# HT32F52342_52 register map
File version: 1.0
CPU: CM0+ r0p1, little endian, no MPU, no FPU, 4 interrupt priority bits
Registers are 32-bit, read-write, reset 0x0 unless marked. A register's access mark holds for its fields unless they carry their own. Offsets are from the block's base; [hi:lo] are bit positions; {n}, {i} and the like mark numbered series.

## USART0
Base 0x40000000
Same registers: USART1 0x40040000
0x00 USART_USRDR
  [8:0] DB
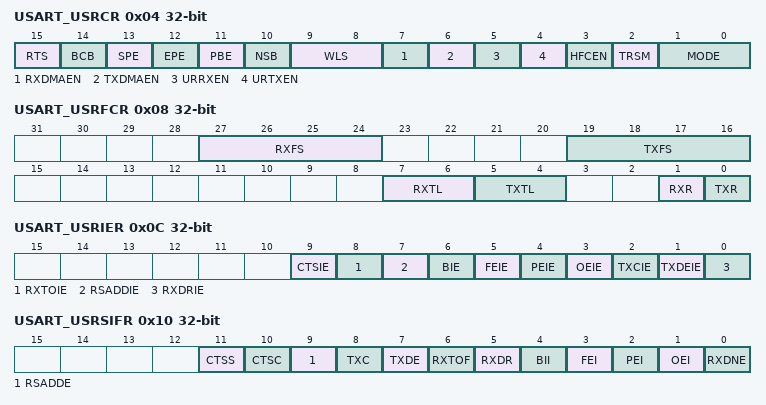
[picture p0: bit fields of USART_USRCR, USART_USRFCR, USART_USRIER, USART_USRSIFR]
0x04 USART_USRCR
  [15] RTS, [14] BCB, [13] SPE, [12] EPE, [11] PBE, [10] NSB, [9:8] WLS, [7] RXDMAEN, [6] TXDMAEN, [5] URRXEN, [4] URTXEN, [3] HFCEN, [2] TRSM, [1:0] MODE
0x08 USART_USRFCR
  [27:24] RXFS, [19:16] TXFS, [7:6] RXTL, [5:4] TXTL, [1] RXR, [0] TXR
0x0C USART_USRIER
  [9] CTSIE, [8] RXTOIE, [7] RSADDIE, [6] BIE, [5] FEIE, [4] PEIE, [3] OEIE, [2] TXCIE, [1] TXDEIE, [0] RXDRIE
0x10 USART_USRSIFR
  [11] CTSS, [10] CTSC, [9] RSADDE, [8] TXC, [7] TXDE, [6] RXTOF, [5] RXDR, [4] BII, [3] FEI, [2] PEI, [1] OEI, [0] RXDNE
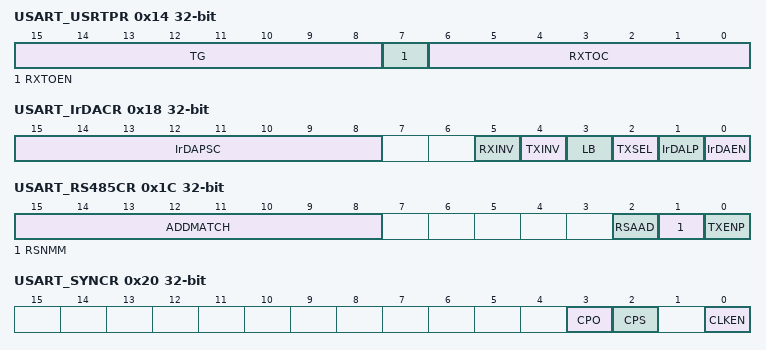
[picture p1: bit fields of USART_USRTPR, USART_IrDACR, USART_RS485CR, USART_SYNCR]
0x14 USART_USRTPR
  [15:8] TG, [7] RXTOEN, [6:0] RXTOC
0x18 USART_IrDACR
  [15:8] IrDAPSC, [5] RXINV, [4] TXINV, [3] LB, [2] TXSEL, [1] IrDALP, [0] IrDAEN
0x1C USART_RS485CR
  [15:8] ADDMATCH, [2] RSAAD, [1] RSNMM, [0] TXENP
0x20 USART_SYNCR
  [3] CPO, [2] CPS, [0] CLKEN
0x24 USART_USRDLR
  [15:0] BRD
0x28 USART_USRTSTR
  [1:0] LBM

## UART0
Base 0x40001000
Same registers: UART1 0x40041000
0x00 UART_URDR
  [8:0] DB
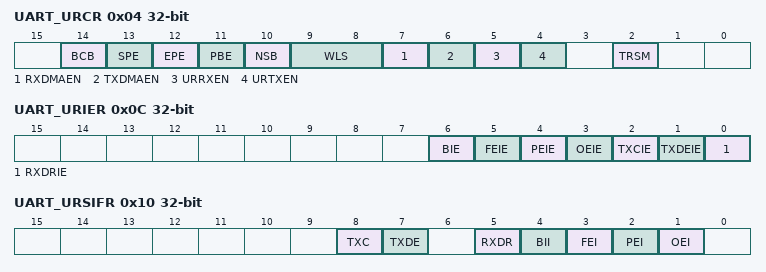
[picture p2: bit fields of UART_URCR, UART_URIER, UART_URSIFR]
0x04 UART_URCR
  [14] BCB, [13] SPE, [12] EPE, [11] PBE, [10] NSB, [9:8] WLS, [7] RXDMAEN, [6] TXDMAEN, [5] URRXEN, [4] URTXEN, [2] TRSM
0x0C UART_URIER
  [6] BIE, [5] FEIE, [4] PEIE, [3] OEIE, [2] TXCIE, [1] TXDEIE, [0] RXDRIE
0x10 UART_URSIFR
  [8] TXC, [7] TXDE, [5] RXDR, [4] BII, [3] FEI, [2] PEI, [1] OEI
0x24 UART_URDLR
  [15:0] BRD
0x28 UART_URTSTR
  [1:0] LBM

## SCI
Base 0x40043000
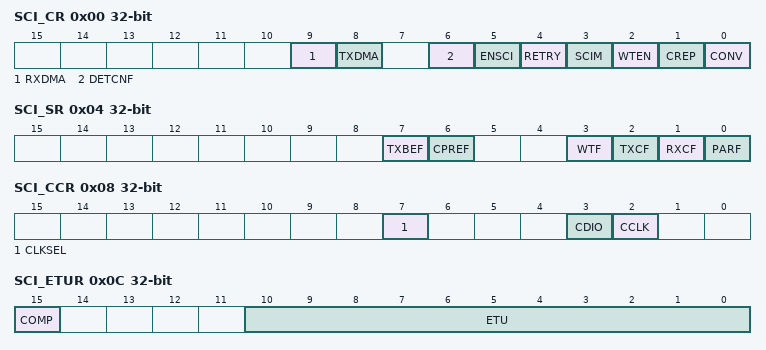
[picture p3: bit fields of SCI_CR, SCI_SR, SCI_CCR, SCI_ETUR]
0x00 SCI_CR
  [9] RXDMA, [8] TXDMA, [6] DETCNF, [5] ENSCI, [4] RETRY, [3] SCIM, [2] WTEN, [1] CREP, [0] CONV
0x04 SCI_SR
  [7] TXBEF, [6] CPREF, [3] WTF, [2] TXCF, [1] RXCF, [0] PARF
0x08 SCI_CCR
  [7] CLKSEL, [3] CDIO, [2] CCLK
0x0C SCI_ETUR
  [15] COMP, [10:0] ETU
0x10 SCI_GTR
  [8:0] GT
0x14 SCI_WTR
  [23:0] WT
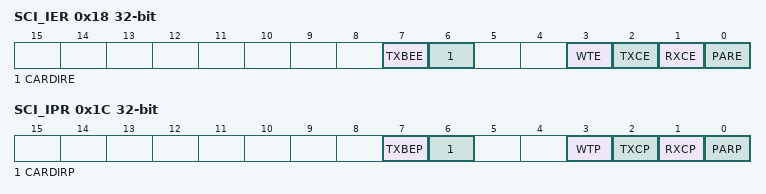
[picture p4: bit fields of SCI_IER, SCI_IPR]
0x18 SCI_IER
  [7] TXBEE, [6] CARDIRE, [3] WTE, [2] TXCE, [1] RXCE, [0] PARE
0x1C SCI_IPR
  [7] TXBEP, [6] CARDIRP, [3] WTP, [2] TXCP, [1] RXCP, [0] PARP
0x20 SCI_TXB
  [7:0] TB
0x24 SCI_RXB
  [7:0] RB
0x28 SCI_PSCR
  [5:0] PSC

## USB
Base 0x400A8000
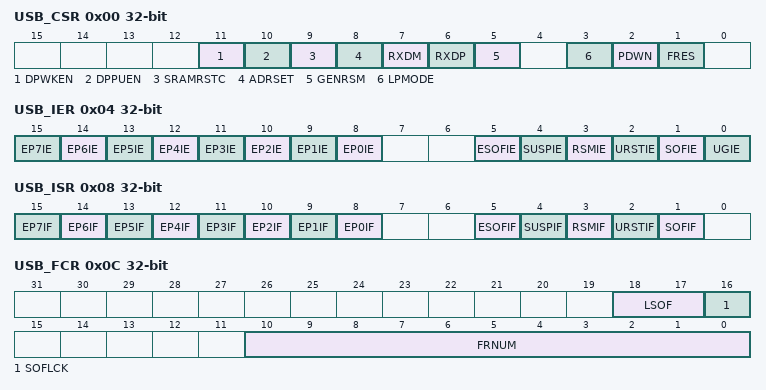
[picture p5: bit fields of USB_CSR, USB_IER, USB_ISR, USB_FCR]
0x00 USB_CSR
  [11] DPWKEN, [10] DPPUEN, [9] SRAMRSTC, [8] ADRSET, [7] RXDM, [6] RXDP, [5] GENRSM, [3] LPMODE, [2] PDWN, [1] FRES
0x04 USB_IER
  [n+8] EP{n}IE (n=0..7), [5] ESOFIE, [4] SUSPIE, [3] RSMIE, [2] URSTIE, [1] SOFIE, [0] UGIE
0x08 USB_ISR
  [n+8] EP{n}IF (n=0..7), [5] ESOFIF, [4] SUSPIF, [3] RSMIF, [2] URSTIF, [1] SOFIF
0x0C USB_FCR
  [18:17] LSOF, [16] SOFLCK, [10:0] FRNUM
0x10 USB_DEVAR
  [6:0] DEVA
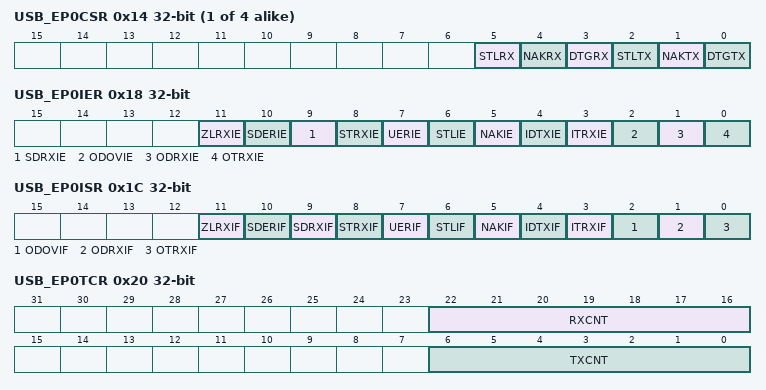
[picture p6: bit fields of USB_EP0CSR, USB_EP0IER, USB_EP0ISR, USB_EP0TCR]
{0x14+0x14*i} USB_EP{i}CSR (i=0..3)
  [5] STLRX, [4] NAKRX, [3] DTGRX, [2] STLTX, [1] NAKTX, [0] DTGTX
0x18 USB_EP0IER
  [11] ZLRXIE, [10] SDERIE, [9] SDRXIE, [8] STRXIE, [7] UERIE, [6] STLIE, [5] NAKIE, [4] IDTXIE, [3] ITRXIE, [2] ODOVIE, [1] ODRXIE, [0] OTRXIE
0x1C USB_EP0ISR
  [11] ZLRXIF, [10] SDERIF, [9] SDRXIF, [8] STRXIF, [7] UERIF, [6] STLIF, [5] NAKIF, [4] IDTXIF, [3] ITRXIF, [2] ODOVIF, [1] ODRXIF, [0] OTRXIF
0x20 USB_EP0TCR
  [22:16] RXCNT, [6:0] TXCNT
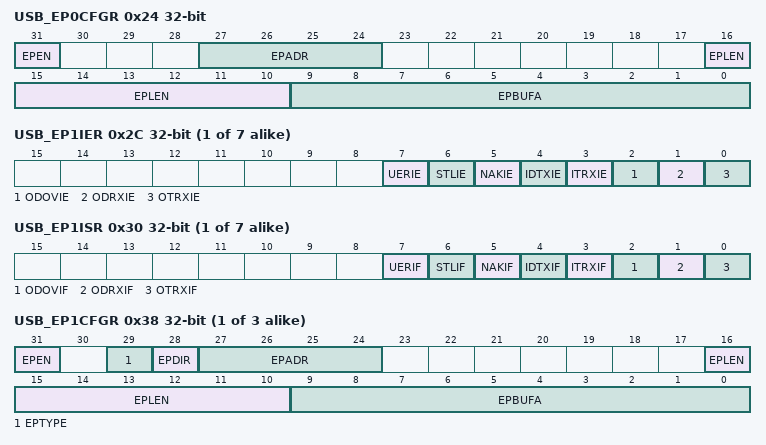
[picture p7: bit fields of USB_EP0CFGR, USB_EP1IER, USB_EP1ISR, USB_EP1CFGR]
0x24 USB_EP0CFGR
  [31] EPEN, [27:24] EPADR, [16:10] EPLEN, [9:0] EPBUFA
{0x18+0x14*i} USB_EP{i}IER (i=1..7)
  [7] UERIE, [6] STLIE, [5] NAKIE, [4] IDTXIE, [3] ITRXIE, [2] ODOVIE, [1] ODRXIE, [0] OTRXIE
{0x1C+0x14*i} USB_EP{i}ISR (i=1..7)
  [7] UERIF, [6] STLIF, [5] NAKIF, [4] IDTXIF, [3] ITRXIF, [2] ODOVIF, [1] ODRXIF, [0] OTRXIF
{0x20+0x14*i} USB_EP{i}TCR (i=1..3)
  [8:0] TCNT
{0x24+0x14*i} USB_EP{i}CFGR (i=1..3)
  [31] EPEN, [29] EPTYPE, [28] EPDIR, [27:24] EPADR, [16:10] EPLEN, [9:0] EPBUFA
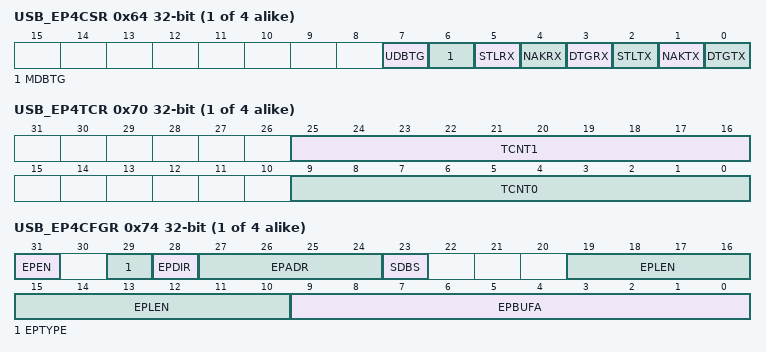
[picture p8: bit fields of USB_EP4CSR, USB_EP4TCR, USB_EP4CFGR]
{0x14+0x14*i} USB_EP{i}CSR (i=4..7)
  [7] UDBTG, [6] MDBTG, [5] STLRX, [4] NAKRX, [3] DTGRX, [2] STLTX, [1] NAKTX, [0] DTGTX
{0x20+0x14*i} USB_EP{i}TCR (i=4..7)
  [25:16] TCNT1, [9:0] TCNT0
{0x24+0x14*i} USB_EP{i}CFGR (i=4..7)
  [31] EPEN, [29] EPTYPE, [28] EPDIR, [27:24] EPADR, [23] SDBS, [19:10] EPLEN, [9:0] EPBUFA

## PDMA
Base 0x40090000
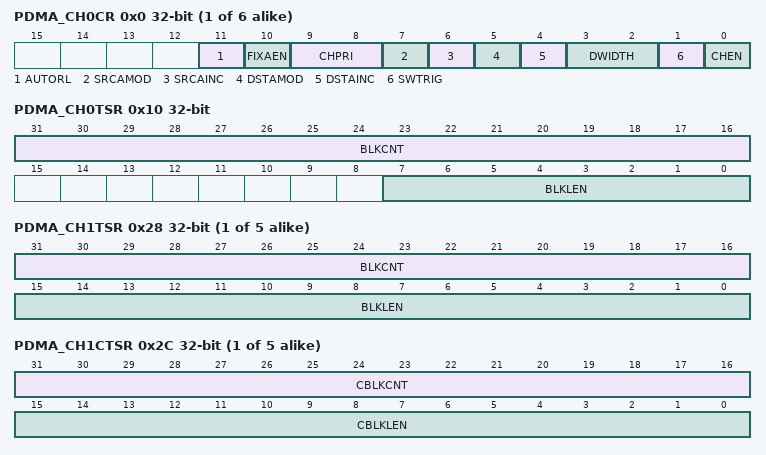
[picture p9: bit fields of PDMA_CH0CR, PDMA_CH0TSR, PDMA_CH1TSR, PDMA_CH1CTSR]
{0x0+0x18*i} PDMA_CH{i}CR (i=0..5)
  [11] AUTORL, [10] FIXAEN, [9:8] CHPRI, [7] SRCAMOD, [6] SRCAINC, [5] DSTAMOD, [4] DSTAINC, [3:2] DWIDTH, [1] SWTRIG, [0] CHEN
{0x4+0x18*i} PDMA_CH{i}SADR (i=0..5)
  [31:0] SADR
{0x8+0x18*i} PDMA_CH{i}DADR (i=0..5)
  [31:0] DADR
0x10 PDMA_CH0TSR
  [31:16] BLKCNT, [7:0] BLKLEN
0x14 PDMA_CH0CTSR
  [31:16] CBLKCNT
{0x10+0x18*i} PDMA_CH{i}TSR (i=1..5)
  [31:16] BLKCNT, [15:0] BLKLEN
{0x14+0x18*i} PDMA_CH{i}CTSR (i=1..5)
  [31:16] CBLKCNT, [15:0] CBLKLEN
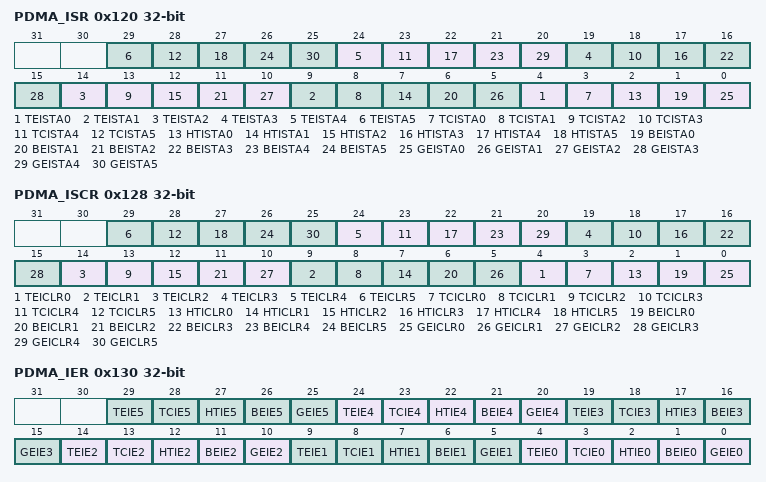
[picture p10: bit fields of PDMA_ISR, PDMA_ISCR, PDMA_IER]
0x120 PDMA_ISR
  [5n+4] TEISTA{n} (n=0..5), [5n+3] TCISTA{n} (n=0..5), [5n+2] HTISTA{n} (n=0..5), [5n+1] BEISTA{n} (n=0..5), [5n] GEISTA{n} (n=0..5)
0x128 PDMA_ISCR
  [5n+4] TEICLR{n} (n=0..5), [5n+3] TCICLR{n} (n=0..5), [5n+2] HTICLR{n} (n=0..5), [5n+1] BEICLR{n} (n=0..5), [5n] GEICLR{n} (n=0..5)
0x130 PDMA_IER
  [5n+4] TEIE{n} (n=0..5), [5n+3] TCIE{n} (n=0..5), [5n+2] HTIE{n} (n=0..5), [5n+1] BEIE{n} (n=0..5), [5n] GEIE{n} (n=0..5)

## EBI
Base 0x40098000
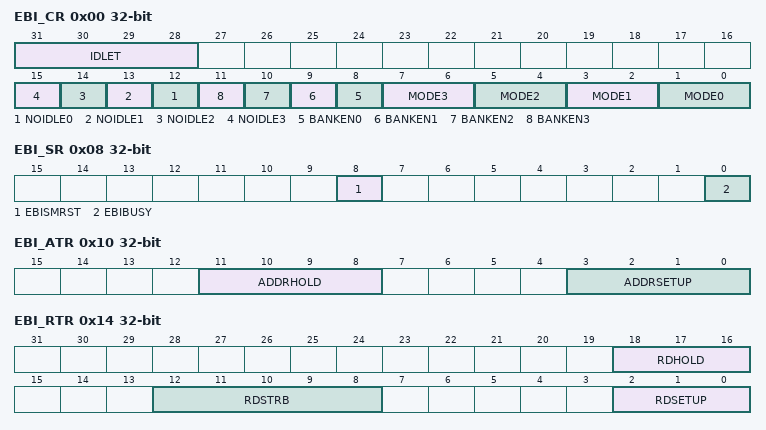
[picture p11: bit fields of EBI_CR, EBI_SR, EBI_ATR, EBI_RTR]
0x00 EBI_CR
  [31:28] IDLET, [n+12] NOIDLE{n} (n=0..3), [n+8] BANKEN{n} (n=0..3), [2n+1:2n] MODE{n} (n=0..3)
0x08 EBI_SR
  [8] EBISMRST, [0] EBIBUSY
0x10 EBI_ATR
  [11:8] ADDRHOLD, [3:0] ADDRSETUP
0x14 EBI_RTR
  [18:16] RDHOLD, [12:8] RDSTRB, [2:0] RDSETUP
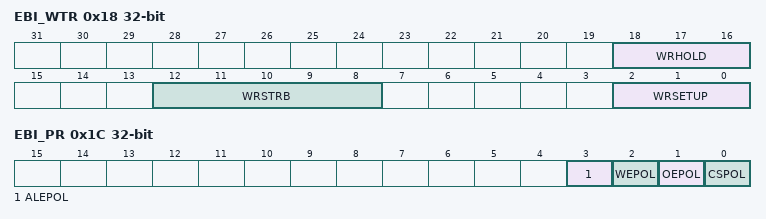
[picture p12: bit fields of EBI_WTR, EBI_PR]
0x18 EBI_WTR
  [18:16] WRHOLD, [12:8] WRSTRB, [2:0] WRSETUP
0x1C EBI_PR
  [3] ALEPOL, [2] WEPOL, [1] OEPOL, [0] CSPOL

## I2S
Base 0x40026000
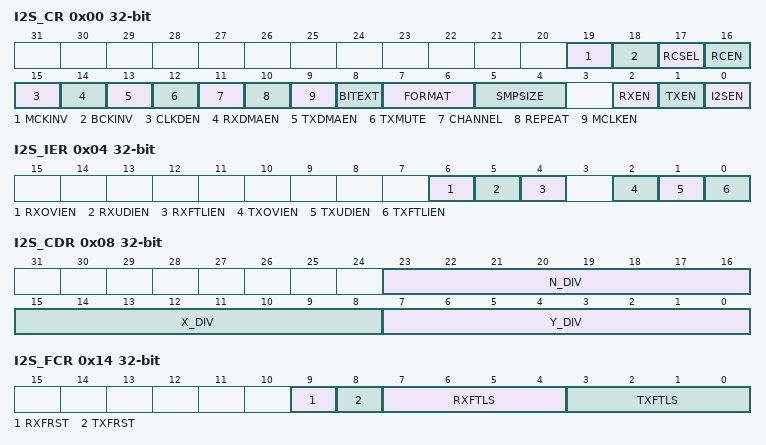
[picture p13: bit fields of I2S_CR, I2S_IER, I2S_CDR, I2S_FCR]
0x00 I2S_CR
  [19] MCKINV, [18] BCKINV, [17] RCSEL, [16] RCEN, [15] CLKDEN, [14] RXDMAEN, [13] TXDMAEN, [12] TXMUTE, [11] CHANNEL, [10] REPEAT, [9] MCLKEN, [8] BITEXT, [7:6] FORMAT, [5:4] SMPSIZE, [2] RXEN, [1] TXEN, [0] I2SEN
0x04 I2S_IER
  [6] RXOVIEN, [5] RXUDIEN, [4] RXFTLIEN, [2] TXOVIEN, [1] TXUDIEN, [0] TXFTLIEN
0x08 I2S_CDR
  [23:16] N_DIV, [15:8] X_DIV, [7:0] Y_DIV
0x0C I2S_TXDR
0x10 I2S_RXDR
0x14 I2S_FCR
  [9] RXFRST, [8] TXFRST, [7:4] RXFTLS, [3:0] TXFTLS
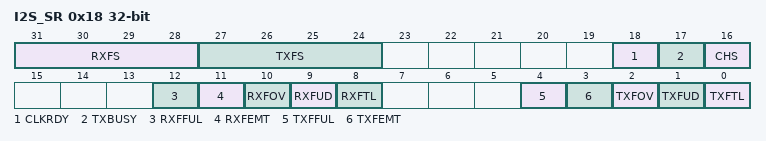
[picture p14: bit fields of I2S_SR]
0x18 I2S_SR
  [31:28] RXFS, [27:24] TXFS, [18] CLKRDY, [17] TXBUSY, [16] CHS, [12] RXFFUL, [11] RXFEMT, [10] RXFOV, [9] RXFUD, [8] RXFTL, [4] TXFFUL, [3] TXFEMT, [2] TXFOV, [1] TXFUD, [0] TXFTL
0x1C I2S_RCNTR
  [19:0] RCNTR

## CRC
Base 0x4008A000
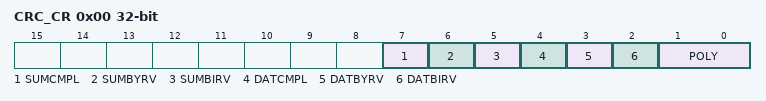
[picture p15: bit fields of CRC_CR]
0x00 CRC_CR
  [7] SUMCMPL, [6] SUMBYRV, [5] SUMBIRV, [4] DATCMPL, [3] DATBYRV, [2] DATBIRV, [1:0] POLY
0x04 CRC_SDR
  [31:0] SEED
0x08 CRC_CSR
  [31:0] CHKSUM
0x0C CRC_DR
  [31:0] DATA
